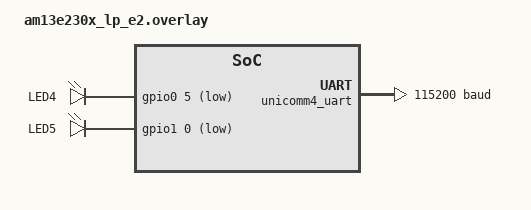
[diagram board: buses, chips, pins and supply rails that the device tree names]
/*
 * Copyright (c) 2026 Texas Instruments Incorporated
 *
 * SPDX-License-Identifier: Apache-2.0
 */

#include <zephyr/dt-bindings/pinctrl/msp-pinctrl.h>
#include <zephyr/dt-bindings/gpio/gpio.h>

/ {
	aliases {
		led0 = &led0;
		led1 = &led1;
	};

	chosen {
		zephyr,console = &unicomm4_uart;
	};

	leds {
		compatible = "gpio-leds";

		led0: led_0 {
			gpios = <&gpio0 5 GPIO_ACTIVE_LOW>;
			label = "LED4";
		};

		led1: led_1 {
			gpios = <&gpio1 0 GPIO_ACTIVE_LOW>;
			label = "LED5";
		};
	};
};

&gpio0 {
	status = "okay";
};

&gpio1 {
	status = "okay";
};

&pinctrl {
	status = "okay";

	pa0_uc4_tx_sda_pico: pa0_uc4_tx_sda_pico {
		pinmux = <TI_AM13E_PINMUX(0, 0, 7)>;
	};

	pa1_uc4_rx_scl_sclk: pa1_uc4_rx_scl_sclk {
		pinmux = <TI_AM13E_PINMUX(0, 1, 7)>;
		input-enable;
	};
};

&unicomm4_uart {
	status = "okay";
	current-speed = <115200>;

	pinctrl-0 = <&pa0_uc4_tx_sda_pico &pa1_uc4_rx_scl_sclk>;
	pinctrl-names = "default";
};
